AUTOSAR XML (schema 4-0-3)
package /AppMode/ApplicationSwComponentTypes
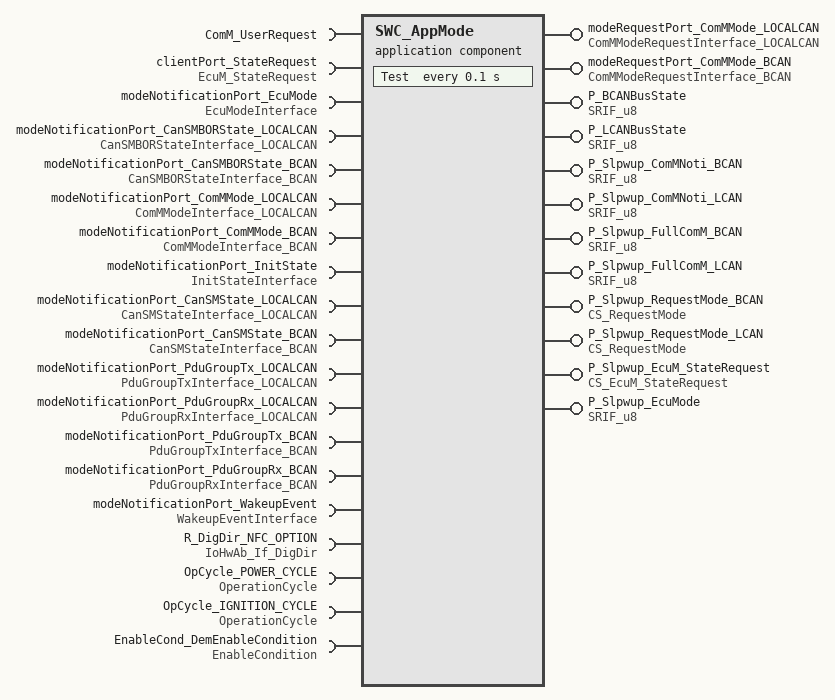
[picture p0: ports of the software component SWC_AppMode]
  application sw component type SWC_AppMode
    require port ComM_UserRequest: client-com-spec=GetCurrentComMode, required-interface=ComM_UserRequest
    require port clientPort_StateRequest: required-com-specs=[ReleaseRUN, RequestRUN, RequestSleep, RequestReset, RequestOff, SetRunState], required-interface=EcuM_StateRequest
    require port modeNotificationPort_EcuMode: mode-switch-receiver-com-spec{enhanced-mode-api=true, mode-group=EcuMode, supports-asynchronous-mode-switch=true}, required-interface=EcuModeInterface
    provide port modeRequestPort_ComMMode_LOCALCAN: nonqueued-sender-com-spec=ComMMode_LOCALCAN, provided-interface=ComMModeRequestInterface_LOCALCAN
    provide port modeRequestPort_ComMMode_BCAN: nonqueued-sender-com-spec=ComMMode_BCAN, provided-interface=ComMModeRequestInterface_BCAN
    12 x require port:
      modeNotificationPort_CanSMBORState_LOCALCAN: mode-switch-receiver-com-spec{enhanced-mode-api=true, mode-group=CanSMBORState_LOCALCAN, supports-asynchronous-mode-switch=true}, required-interface=CanSMBORStateInterface_LOCALCAN
      modeNotificationPort_CanSMBORState_BCAN: mode-switch-receiver-com-spec{enhanced-mode-api=true, mode-group=CanSMBORState_BCAN, supports-asynchronous-mode-switch=true}, required-interface=CanSMBORStateInterface_BCAN
      modeNotificationPort_ComMMode_LOCALCAN: mode-switch-receiver-com-spec{enhanced-mode-api=true, mode-group=ComMMode_LOCALCAN, supports-asynchronous-mode-switch=true}, required-interface=ComMModeInterface_LOCALCAN
      modeNotificationPort_ComMMode_BCAN: mode-switch-receiver-com-spec{enhanced-mode-api=true, mode-group=ComMMode_BCAN, supports-asynchronous-mode-switch=true}, required-interface=ComMModeInterface_BCAN
      modeNotificationPort_InitState: mode-switch-receiver-com-spec{enhanced-mode-api=true, mode-group=InitState, supports-asynchronous-mode-switch=true}, required-interface=InitStateInterface
      modeNotificationPort_CanSMState_LOCALCAN: mode-switch-receiver-com-spec{enhanced-mode-api=true, mode-group=CanSMState_LOCALCAN, supports-asynchronous-mode-switch=true}, required-interface=CanSMStateInterface_LOCALCAN
      modeNotificationPort_CanSMState_BCAN: mode-switch-receiver-com-spec{enhanced-mode-api=true, mode-group=CanSMState_BCAN, supports-asynchronous-mode-switch=true}, required-interface=CanSMStateInterface_BCAN
      modeNotificationPort_PduGroupTx_LOCALCAN: mode-switch-receiver-com-spec{enhanced-mode-api=true, mode-group=PduGroupTx_LOCALCAN, supports-asynchronous-mode-switch=true}, required-interface=PduGroupTxInterface_LOCALCAN
      modeNotificationPort_PduGroupRx_LOCALCAN: mode-switch-receiver-com-spec{enhanced-mode-api=true, mode-group=PduGroupRx_LOCALCAN, supports-asynchronous-mode-switch=true}, required-interface=PduGroupRxInterface_LOCALCAN
      modeNotificationPort_PduGroupTx_BCAN: mode-switch-receiver-com-spec{enhanced-mode-api=true, mode-group=PduGroupTx_BCAN, supports-asynchronous-mode-switch=true}, required-interface=PduGroupTxInterface_BCAN
      modeNotificationPort_PduGroupRx_BCAN: mode-switch-receiver-com-spec{enhanced-mode-api=true, mode-group=PduGroupRx_BCAN, supports-asynchronous-mode-switch=true}, required-interface=PduGroupRxInterface_BCAN
      modeNotificationPort_WakeupEvent: mode-switch-receiver-com-spec{enhanced-mode-api=true, mode-group=WakeupEvent, supports-asynchronous-mode-switch=true}, required-interface=WakeupEventInterface
    10 x provide port:
      P_BCANBusState: nonqueued-sender-com-spec=SR_u8, provided-interface=SRIF_u8
      P_LCANBusState: nonqueued-sender-com-spec=SR_u8, provided-interface=SRIF_u8
      P_Slpwup_ComMNoti_BCAN: nonqueued-sender-com-spec=SR_u8, provided-interface=SRIF_u8
      P_Slpwup_ComMNoti_LCAN: nonqueued-sender-com-spec=SR_u8, provided-interface=SRIF_u8
      P_Slpwup_FullComM_BCAN: nonqueued-sender-com-spec=SR_u8, provided-interface=SRIF_u8
      P_Slpwup_FullComM_LCAN: nonqueued-sender-com-spec=SR_u8, provided-interface=SRIF_u8
      P_Slpwup_RequestMode_BCAN: server-com-spec{operation=RequestComMode, queue-length=1}, provided-interface=CS_RequestMode
      P_Slpwup_RequestMode_LCAN: server-com-spec{operation=RequestComMode, queue-length=1}, provided-interface=CS_RequestMode
      P_Slpwup_EcuM_StateRequest: server-com-spec{operation=RequestState, queue-length=1}, provided-interface=CS_EcuM_StateRequest
      P_Slpwup_EcuMode: nonqueued-sender-com-spec=SR_u8, provided-interface=SRIF_u8
    4 x require port:
      R_DigDir_NFC_OPTION: client-com-spec=ReadDirect, required-interface=IoHwAb_If_DigDir
      OpCycle_POWER_CYCLE: client-com-spec=SetOperationCycleState, required-interface=OperationCycle
      OpCycle_IGNITION_CYCLE: client-com-spec=SetOperationCycleState, required-interface=OperationCycle
      EnableCond_DemEnableCondition: client-com-spec=SetEnableCondition, required-interface=EnableCondition
    behavior SwcIB_AppMode: data-type-mapping=[MAP_AppMode, MAP_ComMMode, MAP_PduRouter]
      timing event TE_AppMode_Test: start-on-event=Test, period=0.1
        disabled-mode:
          modeNotificationPort_EcuMode.EcuMode.ECUM_STATE_STARTUP_ONE
          modeNotificationPort_EcuMode.EcuMode.ECUM_STATE_STARTUP_TWO
          modeNotificationPort_EcuMode.EcuMode.ECUM_STATE_STARTUP_THREE
      25 x swc mode switch event, all with activation=ON-ENTRY:
        SMSE_Entry_EcuModeSwitched_modeNotificationPort_EcuMode_EcuMode_ECUM_STATE_RUN: start-on-event=EcuModeSwitched, mode=modeNotificationPort_EcuMode.EcuMode.ECUM_STATE_RUN
        SMSE_Entry_EcuModeSwitched_modeNotificationPort_EcuMode_EcuMode_ECUM_STATE_SHUTDOWN: start-on-event=EcuModeSwitched, mode=modeNotificationPort_EcuMode.EcuMode.ECUM_STATE_SHUTDOWN
        SMSE_Entry_EcuModeSwitched_modeNotificationPort_EcuMode_EcuMode_ECUM_STATE_PREP_SHUTDOWN: start-on-event=EcuModeSwitched, mode=modeNotificationPort_EcuMode.EcuMode.ECUM_STATE_PREP_SHUTDOWN
        SMSE_Entry_EcuModeSwitched_modeNotificationPort_EcuMode_EcuMode_ECUM_STATE_SLEEP: start-on-event=EcuModeSwitched, mode=modeNotificationPort_EcuMode.EcuMode.ECUM_STATE_SLEEP
        SMSE_Entry_BusOffStateSwitched_modeNotificationPort_CanSMBORState_LOCALCAN_CanSMBORState_LOCALCAN_COMPLETE: start-on-event=CanSMBorStateSwitched_LOCALCAN, mode=modeNotificationPort_CanSMBORState_LOCALCAN.CanSMBORState_LOCALCAN.COMPLETE
        SMSE_Entry_BusOffStateSwitched_modeNotificationPort_CanSMBORState_LOCALCAN_CanSMBORState_LOCALCAN_START: start-on-event=CanSMBorStateSwitched_LOCALCAN, mode=modeNotificationPort_CanSMBORState_LOCALCAN.CanSMBORState_LOCALCAN.START
        SMSE_Entry_BusOffStateSwitched_modeNotificationPort_CanSMBORState_BCAN_CanSMBORState_BCAN_COMPLETE: start-on-event=CanSMBorStateSwitched_BCAN, mode=modeNotificationPort_CanSMBORState_BCAN.CanSMBORState_BCAN.COMPLETE
        SMSE_Entry_BusOffStateSwitched_modeNotificationPort_CanSMBORState_BCAN_CanSMBORState_BCAN_START: start-on-event=CanSMBorStateSwitched_BCAN, mode=modeNotificationPort_CanSMBORState_BCAN.CanSMBORState_BCAN.START
        SMSE_Entry_ComMModeSwitched_LOCALCAN_modeNotificationPort_ComMMode_LOCALCAN_ComMMode_LOCALCAN_NO_COM: start-on-event=ComMModeSwitched_LOCALCAN, mode=modeNotificationPort_ComMMode_LOCALCAN.ComMMode_LOCALCAN.NO_COM
        SMSE_Entry_ComMModeSwitched_LOCALCAN_modeNotificationPort_ComMMode_LOCALCAN_ComMMode_LOCALCAN_SILENT_COM: start-on-event=ComMModeSwitched_LOCALCAN, mode=modeNotificationPort_ComMMode_LOCALCAN.ComMMode_LOCALCAN.SILENT_COM
        SMSE_Entry_ComMModeSwitched_LOCALCAN_modeNotificationPort_ComMMode_LOCALCAN_ComMMode_LOCALCAN_FULL_COM: start-on-event=ComMModeSwitched_LOCALCAN, mode=modeNotificationPort_ComMMode_LOCALCAN.ComMMode_LOCALCAN.FULL_COM
        SMSE_Entry_ComMModeSwitched_BCAN_modeNotificationPort_ComMMode_BCAN_ComMMode_BCAN_NO_COM: start-on-event=ComMModeSwitched_BCAN, mode=modeNotificationPort_ComMMode_BCAN.ComMMode_BCAN.NO_COM
        SMSE_Entry_ComMModeSwitched_BCAN_modeNotificationPort_ComMMode_BCAN_ComMMode_BCAN_SILENT_COM: start-on-event=ComMModeSwitched_BCAN, mode=modeNotificationPort_ComMMode_BCAN.ComMMode_BCAN.SILENT_COM
        SMSE_Entry_ComMModeSwitched_BCAN_modeNotificationPort_ComMMode_BCAN_ComMMode_BCAN_FULL_COM: start-on-event=ComMModeSwitched_BCAN, mode=modeNotificationPort_ComMMode_BCAN.ComMMode_BCAN.FULL_COM
        SMSE_Entry_InitCompleted_modeNotificationPort_InitState_InitState_COMPLETE: start-on-event=InitCompleted, mode=modeNotificationPort_InitState.InitState.COMPLETE
        SMSE_Entry_PduGroupSwitched_LOCALCAN_Tx_modeNotificationPort_PduGroupTx_LOCALCAN_PduGroupTx_LOCALCAN_STOP: start-on-event=PduGroupSwitched_LOCALCAN_Tx, mode=modeNotificationPort_PduGroupTx_LOCALCAN.PduGroupTx_LOCALCAN.STOP
        SMSE_Entry_PduGroupSwitched_LOCALCAN_Tx_modeNotificationPort_PduGroupTx_LOCALCAN_PduGroupTx_LOCALCAN_START: start-on-event=PduGroupSwitched_LOCALCAN_Tx, mode=modeNotificationPort_PduGroupTx_LOCALCAN.PduGroupTx_LOCALCAN.START
        SMSE_Entry_PduGroupSwitched_LOCALCAN_Rx_modeNotificationPort_PduGroupRx_LOCALCAN_PduGroupRx_LOCALCAN_STOP: start-on-event=PduGroupSwitched_LOCALCAN_Rx, mode=modeNotificationPort_PduGroupRx_LOCALCAN.PduGroupRx_LOCALCAN.STOP
        SMSE_Entry_PduGroupSwitched_LOCALCAN_Rx_modeNotificationPort_PduGroupRx_LOCALCAN_PduGroupRx_LOCALCAN_START: start-on-event=PduGroupSwitched_LOCALCAN_Rx, mode=modeNotificationPort_PduGroupRx_LOCALCAN.PduGroupRx_LOCALCAN.START
        SMSE_Entry_PduGroupSwitched_BCAN_Tx_modeNotificationPort_PduGroupTx_BCAN_PduGroupTx_BCAN_STOP: start-on-event=PduGroupSwitched_BCAN_Tx, mode=modeNotificationPort_PduGroupTx_BCAN.PduGroupTx_BCAN.STOP
        SMSE_Entry_PduGroupSwitched_BCAN_Tx_modeNotificationPort_PduGroupTx_BCAN_PduGroupTx_BCAN_START: start-on-event=PduGroupSwitched_BCAN_Tx, mode=modeNotificationPort_PduGroupTx_BCAN.PduGroupTx_BCAN.START
        SMSE_Entry_PduGroupSwitched_BCAN_Rx_modeNotificationPort_PduGroupRx_BCAN_PduGroupRx_BCAN_STOP: start-on-event=PduGroupSwitched_BCAN_Rx, mode=modeNotificationPort_PduGroupRx_BCAN.PduGroupRx_BCAN.STOP
        SMSE_Entry_PduGroupSwitched_BCAN_Rx_modeNotificationPort_PduGroupRx_BCAN_PduGroupRx_BCAN_START: start-on-event=PduGroupSwitched_BCAN_Rx, mode=modeNotificationPort_PduGroupRx_BCAN.PduGroupRx_BCAN.START
        SMSE_Entry_WakeupEventValidated_modeNotificationPort_WakeupEvent_WakeupEvent_LOCALCAN_RX_POLL: start-on-event=WakeupEventValidated, mode=modeNotificationPort_WakeupEvent.WakeupEvent.LOCALCAN_RX_POLL
        SMSE_Entry_WakeupEventValidated_modeNotificationPort_WakeupEvent_WakeupEvent_BCAN_RX_POLL: start-on-event=WakeupEventValidated, mode=modeNotificationPort_WakeupEvent.WakeupEvent.BCAN_RX_POLL
      operation invoked event OIE_RE_Slpwup_RequestMode_BCAN_P_RequestMode_BCAN_RequestComMode: start-on-event=RE_Slpwup_RequestMode_BCAN, operation=P_Slpwup_RequestMode_BCAN.RequestComMode
      operation invoked event OIE_RE_Slpwup_RequestMode_LCAN_P_RequestMode_LCAN_RequestComMode: start-on-event=RE_Slpwup_RequestMode_LCAN, operation=P_Slpwup_RequestMode_LCAN.RequestComMode
      operation invoked event OIE_RE_Slpwup_EcuM_StateRequest_P_Slpwup_EcuM_StateRequest_RequestState: start-on-event=RE_Slpwup_EcuM_StateRequest, operation=P_Slpwup_EcuM_StateRequest.RequestState
      swc mode switch event SMSE_Entry_WakeupEventValidated_modeNotificationPort_WakeupEvent_WakeupEvent_BCAN_RX: start-on-event=WakeupEventValidated, activation=ON-ENTRY, mode=modeNotificationPort_WakeupEvent.WakeupEvent.BCAN_RX
      swc mode switch event SMSE_Entry_WakeupEventValidated_modeNotificationPort_WakeupEvent_WakeupEvent_IGN_WakeUP: start-on-event=WakeupEventValidated, activation=ON-ENTRY, mode=modeNotificationPort_WakeupEvent.WakeupEvent.IGN_WakeUP
      swc mode switch event SMSE_Entry_WakeupEventValidated_modeNotificationPort_WakeupEvent_WakeupEvent_LOCALCAN_RX: start-on-event=WakeupEventValidated, activation=ON-ENTRY, mode=modeNotificationPort_WakeupEvent.WakeupEvent.LOCALCAN_RX
      15 x runnable:
        Test: symbol=AppMode_Test
          data-send-points:
            access DSP_Test_modeRequestPort_ComMMode_LOCALCAN_ComMMode_LOCALCAN: accessed-variable=modeRequestPort_ComMMode_LOCALCAN.ComMMode_LOCALCAN, scope=COMMUNICATION-INTER-ECU
            access DSP_Test_modeRequestPort_ComMMode_BCAN_ComMMode_BCAN: accessed-variable=modeRequestPort_ComMMode_BCAN.ComMMode_BCAN, scope=COMMUNICATION-INTER-ECU
          5 x sync call:
            SSCP_Test_ComM_UserRequest_GetCurrentComMode: operation=ComM_UserRequest.GetCurrentComMode
            SSCP_Test_EcuM_StateRequest_RequestRUN: operation=clientPort_StateRequest.RequestRUN
            SSCP_Test_EcuM_StateRequest_RequestSleep: operation=clientPort_StateRequest.RequestSleep
            SSCP_Test_EcuM_StateRequest_RequestReset: operation=clientPort_StateRequest.RequestReset
            SSCP_Test_EcuM_StateRequest_RequestOff: operation=clientPort_StateRequest.RequestOff
        EcuModeSwitched: can-be-invoked-concurrently=true, symbol=AppMode_EcuModeSwitched
          data-send-points:
            access DSP_EcuModeSwitched_modeRequestPort_ComMMode_LOCALCAN_ComMMode_LOCALCAN: accessed-variable=modeRequestPort_ComMMode_LOCALCAN.ComMMode_LOCALCAN, scope=COMMUNICATION-INTER-ECU
            access DSP_EcuModeSwitched_modeRequestPort_ComMMode_BCAN_ComMMode_BCAN: accessed-variable=modeRequestPort_ComMMode_BCAN.ComMMode_BCAN, scope=COMMUNICATION-INTER-ECU
            access DSP_EcuModeSwitched_P_Slpwup_EcuMode_SR_u8: accessed-variable=P_Slpwup_EcuMode.SR_u8, scope=COMMUNICATION-INTER-ECU
          mode-access-point mode-group=modeNotificationPort_EcuMode.EcuMode:
            ident MRAP_EcuModeSwitched_modeNotificationPort_EcuMode_EcuMode
          sync call SSCP_EcuModeSwitched_EcuM_StateRequest_RequestRUN: operation=clientPort_StateRequest.RequestRUN
          sync call SSCP_EcuModeSwitched_EcuM_StateRequest_SetRunState: operation=clientPort_StateRequest.SetRunState
        CanSMBorStateSwitched_LOCALCAN: can-be-invoked-concurrently=true, symbol=AppMode_CanSMBorStateSwitched_LOCALCAN
          mode-access-point mode-group=modeNotificationPort_CanSMBORState_LOCALCAN.CanSMBORState_LOCALCAN:
            ident MRAP_BusStateSwitched_modeNotificationPort_CanSMBORState_LOCALCAN_CanSMBORState_LOCALCAN
          sync call SSCP_CanSMBorStateSwitched_LOCALCAN_OpCycle_POWER_CYCLE_SetOperationCycleState: operation=OpCycle_POWER_CYCLE.SetOperationCycleState, timeout=0.0
          sync call SSCP_CanSMBorStateSwitched_LOCALCAN_OpCycle_IGNITION_CYCLE_SetOperationCycleState: operation=OpCycle_IGNITION_CYCLE.SetOperationCycleState, timeout=0.0
        CanSMBorStateSwitched_BCAN: can-be-invoked-concurrently=true, symbol=AppMode_CanSMBorStateSwitched_BCAN
          mode-access-point mode-group=modeNotificationPort_CanSMBORState_BCAN.CanSMBORState_BCAN:
            ident MRAP_BusStateSwitched_modeNotificationPort_CanSMBORState_BCAN_CanSMBORState_BCAN
          sync call SSCP_CanSMBorStateSwitched_BCAN_OpCycle_POWER_CYCLE_SetOperationCycleState: operation=OpCycle_POWER_CYCLE.SetOperationCycleState, timeout=0.0
          sync call SSCP_CanSMBorStateSwitched_BCAN_OpCycle_IGNITION_CYCLE_SetOperationCycleState: operation=OpCycle_IGNITION_CYCLE.SetOperationCycleState, timeout=0.0
        ComMModeSwitched_LOCALCAN: symbol=AppMode_ComMModeSwitched_LOCALCAN
          data-send-points:
            access DSP_ComMModeSwitched_LOCALCAN_P_Slpwup_ComMNoti_LCAN_SR_u8: accessed-variable=P_Slpwup_ComMNoti_LCAN.SR_u8, scope=COMMUNICATION-INTER-ECU
            access DSP_ComMModeSwitched_LOCALCAN_P_Slpwup_FullComM_LCAN_SR_u8: accessed-variable=P_Slpwup_FullComM_LCAN.SR_u8, scope=COMMUNICATION-INTER-ECU
          mode-access-point mode-group=modeNotificationPort_ComMMode_LOCALCAN.ComMMode_LOCALCAN:
            ident MRAP_ComMModeSwitched_LOCALCAN_modeNotificationPort_ComMMode_LOCALCAN_ComMMode_LOCALCAN
        ComMModeSwitched_BCAN: symbol=AppMode_ComMModeSwitched_BCAN
          data-send-points:
            access DSP_ComMModeSwitched_BCAN_P_Slpwup_ComMNoti_BCAN_SR_u8: accessed-variable=P_Slpwup_ComMNoti_BCAN.SR_u8, scope=COMMUNICATION-INTER-ECU
            access DSP_ComMModeSwitched_BCAN_P_Slpwup_FullComM_BCAN_SR_u8: accessed-variable=P_Slpwup_FullComM_BCAN.SR_u8, scope=COMMUNICATION-INTER-ECU
          mode-access-point mode-group=modeNotificationPort_ComMMode_BCAN.ComMMode_BCAN:
            ident MRAP_ComMModeSwitched_BCAN_modeNotificationPort_ComMMode_BCAN_ComMMode_BCAN
        InitCompleted: can-be-invoked-concurrently=true, symbol=AppMode_InitCompleted
          mode-access-point mode-group=modeNotificationPort_InitState.InitState:
            ident MRAP_InitCompleted_modeNotificationPort_InitState_InitState
          4 x sync call:
            SSCP_InitCompleted_R_DigDir_NFC_OPTION_ReadDirect: operation=R_DigDir_NFC_OPTION.ReadDirect
            SSCP_InitCompleted_OpCycle_IGNITION_CYCLE_SetOperationCycleState: operation=OpCycle_IGNITION_CYCLE.SetOperationCycleState
            SSCP_InitCompleted_OpCycle_POWER_CYCLE_SetOperationCycleState: operation=OpCycle_POWER_CYCLE.SetOperationCycleState
            SSCP_InitCompleted_EnableCond_DemEnableCondition_SetEnableCondition: operation=EnableCond_DemEnableCondition.SetEnableCondition
        PduGroupSwitched_LOCALCAN_Tx: symbol=AppMode_PduGroupSwitched_LOCALCAN_Tx
          data-send-points:
            access DSP_PduGroupSwitched_LOCALCAN_Tx_P_LCanTxState_SR_u8: accessed-variable=P_LCANBusState.SR_u8, scope=COMMUNICATION-INTER-ECU
          mode-access-point mode-group=modeNotificationPort_PduGroupTx_LOCALCAN.PduGroupTx_LOCALCAN:
            ident MRAP_PduGroupSwitched_LOCALCAN_Tx_modeNotificationPort_PduGroupTx_LOCALCAN_PduGroupTx_LOCALCAN
        PduGroupSwitched_LOCALCAN_Rx: symbol=AppMode_PduGroupSwitched_LOCALCAN_Rx
          mode-access-point mode-group=modeNotificationPort_PduGroupRx_LOCALCAN.PduGroupRx_LOCALCAN:
            ident MRAP_PduGroupSwitched_LOCALCAN_Rx_modeNotificationPort_PduGroupRx_LOCALCAN_PduGroupRx_LOCALCAN
        PduGroupSwitched_BCAN_Tx: symbol=AppMode_PduGroupSwitched_BCAN_Tx
          data-send-points:
            access DSP_PduGroupSwitched_BCAN_Tx_P_BCanTxState_SR_u8: accessed-variable=P_BCANBusState.SR_u8, scope=COMMUNICATION-INTER-ECU
          mode-access-point mode-group=modeNotificationPort_PduGroupTx_BCAN.PduGroupTx_BCAN:
            ident MRAP_PduGroupSwitched_BCAN_Tx_modeNotificationPort_PduGroupTx_BCAN_PduGroupTx_BCAN
        PduGroupSwitched_BCAN_Rx: symbol=AppMode_PduGroupSwitched_BCAN_Rx
          mode-access-point mode-group=modeNotificationPort_PduGroupRx_BCAN.PduGroupRx_BCAN:
            ident MRAP_PduGroupSwitched_BCAN_Rx_modeNotificationPort_PduGroupRx_BCAN_PduGroupRx_BCAN
        WakeupEventValidated: can-be-invoked-concurrently=true, symbol=AppMode_WakeupEventValidated
          mode-access-point mode-group=modeNotificationPort_WakeupEvent.WakeupEvent:
            ident MRAP_WakeupEventValidated_modeNotificationPort_WakeupEvent_WakeupEvent
          sync call SSCP_WakeupEventValidated_EcuM_StateRequest_RequestRUN: operation=clientPort_StateRequest.RequestRUN, timeout=0.0
        RE_Slpwup_RequestMode_BCAN: symbol=Slpwup_RequestMode_BCAN
        RE_Slpwup_RequestMode_LCAN: symbol=Slpwup_RequestMode_LCAN
        RE_Slpwup_EcuM_StateRequest: symbol=Slpwup_EcuM_StateRequest
      swc service dependency SwcServiceDependency_BswM
        assigned-ports:
          port-prototype=modeNotificationPort_EcuMode, role=Custom
          port-prototype=modeRequestPort_ComMMode_LOCALCAN, role=Custom
          port-prototype=modeRequestPort_ComMMode_BCAN, role=Custom
          port-prototype=modeNotificationPort_CanSMBORState_LOCALCAN, role=Custom
          port-prototype=modeNotificationPort_CanSMBORState_BCAN, role=Custom
          port-prototype=modeNotificationPort_ComMMode_LOCALCAN, role=Custom
          port-prototype=modeNotificationPort_ComMMode_BCAN, role=Custom
          port-prototype=modeNotificationPort_InitState, role=Custom
          port-prototype=modeNotificationPort_CanSMState_LOCALCAN, role=Custom
          port-prototype=modeNotificationPort_CanSMState_BCAN, role=Custom
          port-prototype=modeNotificationPort_PduGroupTx_LOCALCAN, role=Custom
          port-prototype=modeNotificationPort_PduGroupRx_LOCALCAN, role=Custom
          port-prototype=modeNotificationPort_PduGroupTx_BCAN, role=Custom
          port-prototype=modeNotificationPort_PduGroupRx_BCAN, role=Custom
          port-prototype=modeNotificationPort_WakeupEvent, role=Custom
        service-needs:
          bsw mgr needs BswMgrNeeds
